AUTOSAR XML (schema 4-0-3)
package /ComponentTypes
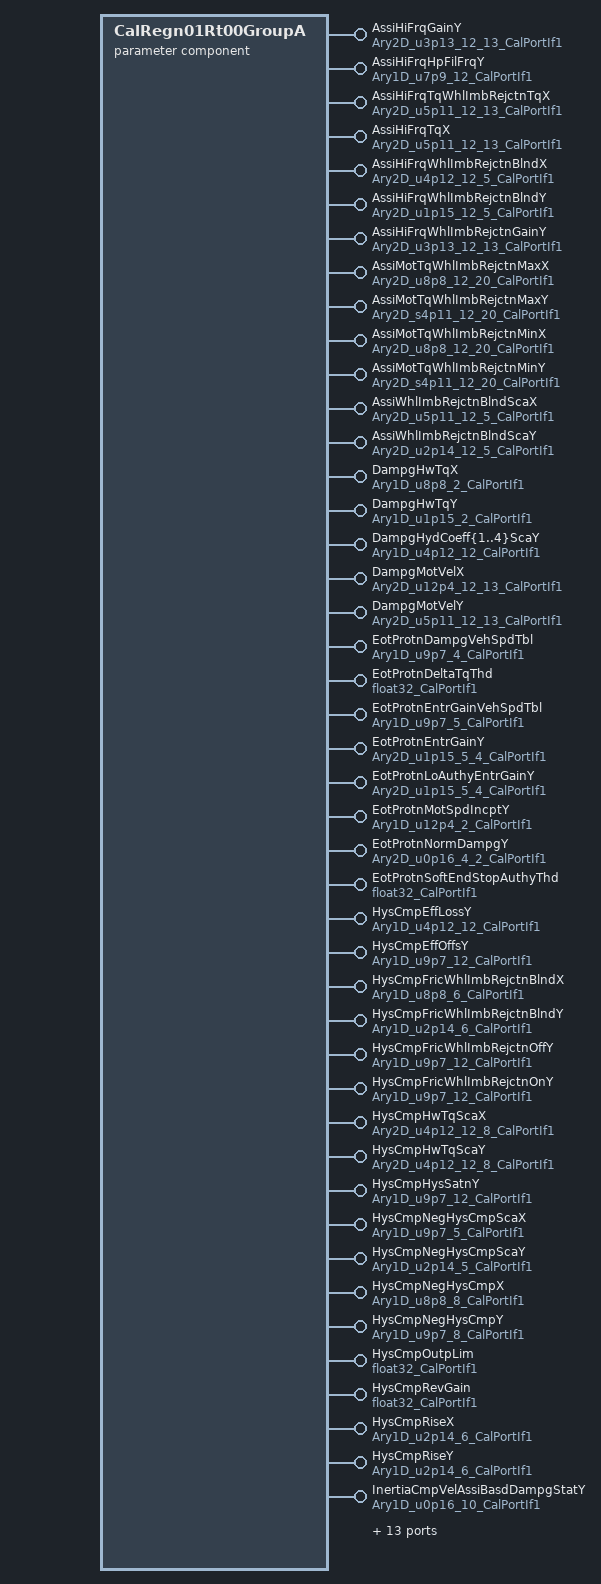
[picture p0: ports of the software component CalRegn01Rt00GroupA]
  parameter sw component type CalRegn01Rt00GroupA
    60 x provide port:
      AssiHiFrqGainY: parameter-provide-com-spec{init-value=12 x [2048, 1638, 1065, 655, 328, 82, 0, 0, 0, 0, 0, 0, 0], parameter=Ary2D}, provided-interface=Ary2D_u3p13_12_13_CalPortIf1
      AssiHiFrqHpFilFrqY: parameter-provide-com-spec{init-value=12 x 4096, parameter=Ary1D}, provided-interface=Ary1D_u7p9_12_CalPortIf1
      AssiHiFrqTqWhlImbRejctnTqX: parameter-provide-com-spec{init-value=12 x [0, 512, 1024, 1536, 2048, 2560, 3072, 4096, 8192, 12288, 15360, 15872, 16384], parameter=Ary2D}, provided-interface=Ary2D_u5p11_12_13_CalPortIf1
      AssiHiFrqTqX: parameter-provide-com-spec{init-value=12 x [0, 512, 1024, 1536, 2048, 2560, 3072, 4096, 8192, 12288, 15360, 15872, 16384], parameter=Ary2D}, provided-interface=Ary2D_u5p11_12_13_CalPortIf1
      AssiHiFrqWhlImbRejctnBlndX: parameter-provide-com-spec{init-value=12 x [0, 1024, 2048, 3072, 4506], parameter=Ary2D}, provided-interface=Ary2D_u4p12_12_5_CalPortIf1
      AssiHiFrqWhlImbRejctnBlndY: parameter-provide-com-spec{init-value=12 x 5 x 0, parameter=Ary2D}, provided-interface=Ary2D_u1p15_12_5_CalPortIf1
      AssiHiFrqWhlImbRejctnGainY: parameter-provide-com-spec{init-value=12 x [2048, 1638, 1065, 655, 328, 82, 0, 0, 0, 0, 0, 0, 0], parameter=Ary2D}, provided-interface=Ary2D_u3p13_12_13_CalPortIf1
      AssiMotTqWhlImbRejctnMaxX: parameter-provide-com-spec{init-value=[[0, 26, 53, 63, 74, 86, 98, 110, 123, 134, 146, 159, 170, 182, 194, 205, 256, 372, 1220, 2560], [0, 26, 78, 101, 123, 148, 171, 196, 220, 243, 267, 290, 315, 339, 362, 435, 563, 719, 1624, 2560], [0, 51, 80, 113, 145, 176, 205, 238, 266, 297, 330, 360, 391, 422, 452, 538, 717, 916, 2216, 2560], [0, 51, 80, 110, 146, 173, 205, 237, 266, 299, 330, 360, 392, 423, 452, 484, 640, 917, 947, 2560], [0, 51, 80, 111, 143, 177, 207, 238, 267, 300, 330, 359, 392, 422, 453, 483, 640, 819, 947, 2560], [0, 51, 79, 111, 139, 174, 206, 236, 267, 300, 334, 366, 396, 428, 460, 494, 640, 819, 972, 2560], [0, 51, 80, 106, 142, 175, 205, 239, 270, 300, 332, 366, 398, 429, 462, 494, 640, 819, 972, 2560], [0, 51, 100, 130, 163, 194, 229, 261, 291, 324, 355, 388, 420, 451, 483, 515, 640, 819, 998, 2560], [0, 51, 100, 130, 164, 196, 232, 260, 297, 327, 360, 396, 430, 462, 493, 527, 666, 819, 1024, 2560], [0, 51, 100, 130, 164, 196, 232, 260, 297, 327, 360, 396, 430, 462, 493, 527, 666, 819, 1024, 2560], [0, 51, 100, 130, 164, 196, 232, 260, 297, 327, 360, 396, 430, 462, 493, 527, 666, 819, 1024, 2560], [0, 51, 100, 130, 164, 196, 232, 260, 297, 327, 360, 396, 430, 462, 493, 527, 666, 819, 1024, 2560]], parameter=Ary2D}, provided-interface=Ary2D_u8p8_12_20_CalPortIf1
      AssiMotTqWhlImbRejctnMaxY: parameter-provide-com-spec{init-value=[[0, 0, 48, 72, 104, 144, 192, 248, 312, 376, 448, 536, 616, 712, 816, 920, 1536, 3128, 17904, 17904], [0, 0, 64, 104, 152, 216, 288, 376, 472, 576, 696, 824, 968, 1120, 1280, 1761, 3072, 5120, 17904, 17904], [0, 0, 32, 80, 136, 200, 272, 360, 448, 552, 672, 792, 928, 1072, 1224, 1741, 3031, 4728, 17904, 17904], [0, 0, 32, 72, 128, 176, 240, 312, 384, 472, 560, 656, 760, 872, 984, 1112, 2048, 3568, 3792, 15632], [0, 0, 32, 72, 120, 176, 232, 296, 360, 440, 520, 600, 696, 792, 896, 1000, 1741, 2642, 3320, 13472], [0, 0, 32, 72, 112, 168, 224, 280, 344, 416, 496, 576, 656, 744, 840, 944, 1536, 2314, 3024, 11632], [0, 0, 32, 64, 112, 160, 208, 264, 320, 376, 440, 512, 584, 656, 736, 816, 1311, 1925, 2456, 9120], [0, 0, 48, 80, 120, 160, 208, 256, 304, 360, 416, 480, 544, 608, 680, 752, 1126, 1720, 2264, 8272], [0, 0, 48, 80, 120, 160, 208, 248, 304, 352, 408, 472, 536, 600, 664, 736, 1024, 1536, 2160, 7528], [0, 0, 48, 80, 120, 160, 208, 248, 304, 352, 408, 472, 536, 600, 664, 736, 1024, 1536, 2160, 7528], [0, 0, 48, 80, 120, 160, 208, 248, 304, 352, 408, 472, 536, 600, 664, 736, 1024, 1536, 2160, 7528], [0, 0, 48, 80, 120, 160, 208, 248, 304, 352, 408, 472, 536, 600, 664, 736, 1024, 1536, 2160, 7528]], parameter=Ary2D}, provided-interface=Ary2D_s4p11_12_20_CalPortIf1
      AssiMotTqWhlImbRejctnMinX: parameter-provide-com-spec{init-value=[[0, 26, 53, 63, 74, 86, 98, 110, 123, 134, 146, 159, 170, 182, 194, 205, 256, 372, 1220, 2560], [0, 26, 78, 101, 123, 148, 171, 196, 220, 243, 267, 290, 315, 339, 362, 435, 563, 719, 1624, 2560], [0, 51, 80, 113, 145, 176, 205, 238, 266, 297, 330, 360, 391, 422, 452, 538, 717, 916, 2216, 2560], [0, 51, 80, 110, 146, 173, 205, 237, 266, 299, 330, 360, 392, 423, 452, 484, 640, 917, 947, 2560], [0, 51, 80, 111, 143, 177, 207, 238, 267, 300, 330, 359, 392, 422, 453, 483, 640, 819, 947, 2560], [0, 51, 79, 111, 139, 174, 206, 236, 267, 300, 334, 366, 396, 428, 460, 494, 640, 819, 972, 2560], [0, 51, 80, 106, 142, 175, 205, 239, 270, 300, 332, 366, 398, 429, 462, 494, 640, 819, 972, 2560], [0, 51, 100, 130, 163, 194, 229, 261, 291, 324, 355, 388, 420, 451, 483, 515, 640, 819, 998, 2560], [0, 51, 100, 130, 164, 196, 232, 260, 297, 327, 360, 396, 430, 462, 493, 527, 666, 819, 1024, 2560], [0, 51, 100, 130, 164, 196, 232, 260, 297, 327, 360, 396, 430, 462, 493, 527, 666, 819, 1024, 2560], [0, 51, 100, 130, 164, 196, 232, 260, 297, 327, 360, 396, 430, 462, 493, 527, 666, 819, 1024, 2560], [0, 51, 100, 130, 164, 196, 232, 260, 297, 327, 360, 396, 430, 462, 493, 527, 666, 819, 1024, 2560]], parameter=Ary2D}, provided-interface=Ary2D_u8p8_12_20_CalPortIf1
      AssiMotTqWhlImbRejctnMinY: parameter-provide-com-spec{init-value=[[0, 0, 48, 72, 104, 144, 192, 248, 312, 376, 448, 536, 616, 712, 816, 920, 1536, 3128, 17904, 17904], [0, 0, 64, 104, 152, 216, 288, 376, 472, 576, 696, 824, 968, 1120, 1280, 1761, 3072, 5120, 17904, 17904], [0, 0, 32, 80, 136, 200, 272, 360, 448, 552, 672, 792, 928, 1072, 1224, 1741, 3031, 4728, 17904, 17904], [0, 0, 32, 72, 128, 176, 240, 312, 384, 472, 560, 656, 760, 872, 984, 1112, 2048, 3568, 3792, 15632], [0, 0, 32, 72, 120, 176, 232, 296, 360, 440, 520, 600, 696, 792, 896, 1000, 1741, 2642, 3320, 13472], [0, 0, 32, 72, 112, 168, 224, 280, 344, 416, 496, 576, 656, 744, 840, 944, 1536, 2314, 3024, 11632], [0, 0, 32, 64, 112, 160, 208, 264, 320, 376, 440, 512, 584, 656, 736, 816, 1311, 1925, 2456, 9120], [0, 0, 48, 80, 120, 160, 208, 256, 304, 360, 416, 480, 544, 608, 680, 752, 1126, 1720, 2264, 8272], [0, 0, 48, 80, 120, 160, 208, 248, 304, 352, 408, 472, 536, 600, 664, 736, 1024, 1536, 2160, 7528], [0, 0, 48, 80, 120, 160, 208, 248, 304, 352, 408, 472, 536, 600, 664, 736, 1024, 1536, 2160, 7528], [0, 0, 48, 80, 120, 160, 208, 248, 304, 352, 408, 472, 536, 600, 664, 736, 1024, 1536, 2160, 7528], [0, 0, 48, 80, 120, 160, 208, 248, 304, 352, 408, 472, 536, 600, 664, 736, 1024, 1536, 2160, 7528]], parameter=Ary2D}, provided-interface=Ary2D_s4p11_12_20_CalPortIf1
      AssiWhlImbRejctnBlndScaX: parameter-provide-com-spec{init-value=12 x [0, 512, 1024, 1536, 2253], parameter=Ary2D}, provided-interface=Ary2D_u5p11_12_5_CalPortIf1
      AssiWhlImbRejctnBlndScaY: parameter-provide-com-spec{init-value=12 x 5 x 0, parameter=Ary2D}, provided-interface=Ary2D_u2p14_12_5_CalPortIf1
      DampgHwTqX: parameter-provide-com-spec{init-value=[2048, 2560], parameter=Ary1D}, provided-interface=Ary1D_u8p8_2_CalPortIf1
      DampgHwTqY: parameter-provide-com-spec{init-value=[32768, 0], parameter=Ary1D}, provided-interface=Ary1D_u1p15_2_CalPortIf1
      DampgHydCoeff{1..4}ScaY: parameter-provide-com-spec{init-value=12 x 4096, parameter=Ary1D}, provided-interface=Ary1D_u4p12_12_CalPortIf1
      DampgMotVelX: parameter-provide-com-spec{init-value=12 x [33, 163, 342, 554, 872, 1260, 1663, 2032, 2401, 2771, 3509, 4433, 5910], parameter=Ary2D}, provided-interface=Ary2D_u12p4_12_13_CalPortIf1
      DampgMotVelY: parameter-provide-com-spec{init-value=[13 x 0, 13 x 0, 13 x 0, 13 x 0, [0, 0, 1, 3, 7, 14, 24, 36, 50, 67, 107, 171, 304], [1, 5, 13, 25, 48, 85, 132, 184, 245, 313, 476, 725, 1233], [5, 25, 54, 93, 159, 251, 360, 472, 597, 733, 1041, 1493, 2370], [10, 49, 106, 180, 301, 467, 659, 855, 1068, 1299, 1814, 2559, 3981], [10, 49, 106, 180, 301, 467, 659, 855, 1068, 1299, 1814, 2559, 3981], [10, 49, 106, 180, 301, 467, 659, 855, 1068, 1299, 1814, 2559, 3981], [10, 49, 106, 180, 301, 467, 659, 855, 1068, 1299, 1814, 2559, 3981], [10, 49, 106, 180, 301, 467, 659, 855, 1068, 1299, 1814, 2559, 3981]], parameter=Ary2D}, provided-interface=Ary2D_u5p11_12_13_CalPortIf1
      EotProtnDampgVehSpdTbl: parameter-provide-com-spec{init-value=[0, 640, 1280, 2560], parameter=Ary1D}, provided-interface=Ary1D_u9p7_4_CalPortIf1
      EotProtnDeltaTqThd: parameter-provide-com-spec{init-value=0, parameter=Val}, provided-interface=float32_CalPortIf1
      EotProtnEntrGainVehSpdTbl: parameter-provide-com-spec{init-value=[0, 640, 1280, 1920, 2560], parameter=Ary1D}, provided-interface=Ary1D_u9p7_5_CalPortIf1
      EotProtnEntrGainY: parameter-provide-com-spec{init-value=5 x [0, 10813, 21627, 32768], parameter=Ary2D}, provided-interface=Ary2D_u1p15_5_4_CalPortIf1
      EotProtnLoAuthyEntrGainY: parameter-provide-com-spec{init-value=5 x [0, 9830, 22938, 32768], parameter=Ary2D}, provided-interface=Ary2D_u1p15_5_4_CalPortIf1
      EotProtnMotSpdIncptY: parameter-provide-com-spec{init-value=[10400, 10400], parameter=Ary1D}, provided-interface=Ary1D_u12p4_2_CalPortIf1
      EotProtnNormDampgY: parameter-provide-com-spec{init-value=[[0, 262], [0, 262], [0, 262], [0, 262]], parameter=Ary2D}, provided-interface=Ary2D_u0p16_4_2_CalPortIf1
      EotProtnSoftEndStopAuthyThd: parameter-provide-com-spec{init-value=0.9, parameter=Val}, provided-interface=float32_CalPortIf1
      HysCmpEffLossY: parameter-provide-com-spec{init-value=12 x 0, parameter=Ary1D}, provided-interface=Ary1D_u4p12_12_CalPortIf1
      HysCmpEffOffsY: parameter-provide-com-spec{init-value=12 x 0, parameter=Ary1D}, provided-interface=Ary1D_u9p7_12_CalPortIf1
      HysCmpFricWhlImbRejctnBlndX: parameter-provide-com-spec{init-value=[0, 51, 102, 154, 205, 256], parameter=Ary1D}, provided-interface=Ary1D_u8p8_6_CalPortIf1
      HysCmpFricWhlImbRejctnBlndY: parameter-provide-com-spec{init-value=6 x 0, parameter=Ary1D}, provided-interface=Ary1D_u2p14_6_CalPortIf1
      HysCmpFricWhlImbRejctnOffY: parameter-provide-com-spec{init-value=12 x 0, parameter=Ary1D}, provided-interface=Ary1D_u9p7_12_CalPortIf1
      HysCmpFricWhlImbRejctnOnY: parameter-provide-com-spec{init-value=12 x 0, parameter=Ary1D}, provided-interface=Ary1D_u9p7_12_CalPortIf1
      HysCmpHwTqScaX: parameter-provide-com-spec{init-value=12 x [0, 815, 1634, 2458, 4096, 5730, 8192, 40960], parameter=Ary2D}, provided-interface=Ary2D_u4p12_12_8_CalPortIf1
      HysCmpHwTqScaY: parameter-provide-com-spec{init-value=12 x 8 x 4096, parameter=Ary2D}, provided-interface=Ary2D_u4p12_12_8_CalPortIf1
      HysCmpHysSatnY: parameter-provide-com-spec{init-value=12 x 1280, parameter=Ary1D}, provided-interface=Ary1D_u9p7_12_CalPortIf1
      HysCmpNegHysCmpScaX: parameter-provide-com-spec{init-value=[0, 128, 256, 384, 512], parameter=Ary1D}, provided-interface=Ary1D_u9p7_5_CalPortIf1
      HysCmpNegHysCmpScaY: parameter-provide-com-spec{init-value=5 x 16384, parameter=Ary1D}, provided-interface=Ary1D_u2p14_5_CalPortIf1
      HysCmpNegHysCmpX: parameter-provide-com-spec{init-value=[0, 26, 51, 102, 154, 205, 230, 256], parameter=Ary1D}, provided-interface=Ary1D_u8p8_8_CalPortIf1
      HysCmpNegHysCmpY: parameter-provide-com-spec{init-value=8 x 0, parameter=Ary1D}, provided-interface=Ary1D_u9p7_8_CalPortIf1
      HysCmpOutpLim: parameter-provide-com-spec{init-value=16, parameter=Val}, provided-interface=float32_CalPortIf1
      HysCmpRevGain: parameter-provide-com-spec{init-value=6, parameter=Val}, provided-interface=float32_CalPortIf1
      HysCmpRiseX: parameter-provide-com-spec{init-value=[0, 1556, 2097, 2540, 2982, 3277], parameter=Ary1D}, provided-interface=Ary1D_u2p14_6_CalPortIf1
      HysCmpRiseY: parameter-provide-com-spec{init-value=[0, 9863, 12878, 14811, 15974, 16384], parameter=Ary1D}, provided-interface=Ary1D_u2p14_6_CalPortIf1
      InertiaCmpVelAssiBasdDampgStatY: parameter-provide-com-spec{init-value=10 x 0, parameter=Ary1D}, provided-interface=Ary1D_u0p16_10_CalPortIf1
      InertiaCmpVelDampgFilFrq: parameter-provide-com-spec{init-value=12 x 8192, parameter=Ary1D}, provided-interface=Ary1D_u7p9_12_CalPortIf1
      InertiaCmpVelDampgFilFrqWhlImbRejctnOn: parameter-provide-com-spec{init-value=12 x 8192, parameter=Ary1D}, provided-interface=Ary1D_u7p9_12_CalPortIf1
      InertiaCmpVelDampgSpdBlndY: parameter-provide-com-spec{init-value=[32768, 32768, 9830, 6554, 3277, 0, 0, 0, 0, 0, 0, 0], parameter=Ary1D}, provided-interface=Ary1D_u1p15_12_CalPortIf1
      InertiaCmpVelDampgWhlImbRejctnBlndX: parameter-provide-com-spec{init-value=[208, 432, 640, 848, 1056], parameter=Ary1D}, provided-interface=Ary1D_u4p12_5_CalPortIf1
      InertiaCmpVelDampgWhlImbRejctnBlndY: parameter-provide-com-spec{init-value=5 x 0, parameter=Ary1D}, provided-interface=Ary1D_u1p15_5_CalPortIf1
      RtnHwAgOffsCalcdX: parameter-provide-com-spec{init-value=9 x [0, 8, 16, 80, 160, 320, 480, 720, 960, 1440, 1920, 2880, 4320, 5760, 7200, 8640], parameter=Ary2D}, provided-interface=Ary2D_u12p4_9_16_CalPortIf1
      RtnHwAgOffsCalcdY: parameter-provide-com-spec{init-value=9 x 16 x 0, parameter=Ary2D}, provided-interface=Ary2D_u5p11_9_16_CalPortIf1
      RtnScaTqX: parameter-provide-com-spec{init-value=9 x [0, 128, 256, 512, 768, 1024, 1280, 2560], parameter=Ary2D}, provided-interface=Ary2D_u8p8_9_8_CalPortIf1
      RtnScaTqY: parameter-provide-com-spec{init-value=9 x 8 x 256, parameter=Ary2D}, provided-interface=Ary2D_u8p8_9_8_CalPortIf1
      RtnScaVelX: parameter-provide-com-spec{init-value=9 x [0, 20480, 21504, 21504], parameter=Ary2D}, provided-interface=Ary2D_u7p9_9_4_CalPortIf1
      RtnScaVelY: parameter-provide-com-spec{init-value=9 x [256, 256, 256, 256], parameter=Ary2D}, provided-interface=Ary2D_u8p8_9_4_CalPortIf1
      RtnVehSpdSeln: parameter-provide-com-spec{init-value=[0, 384, 896, 1536, 2560, 3840, 5760, 7680, 10240], parameter=Ary1D}, provided-interface=Ary1D_u9p7_9_CalPortIf1
      TEstimnMagAmbMplr: parameter-provide-com-spec{init-value=[0.01, 0.01, 0.01], parameter=Ary1D}, provided-interface=Ary1D_f32_3_CalPortIf1
